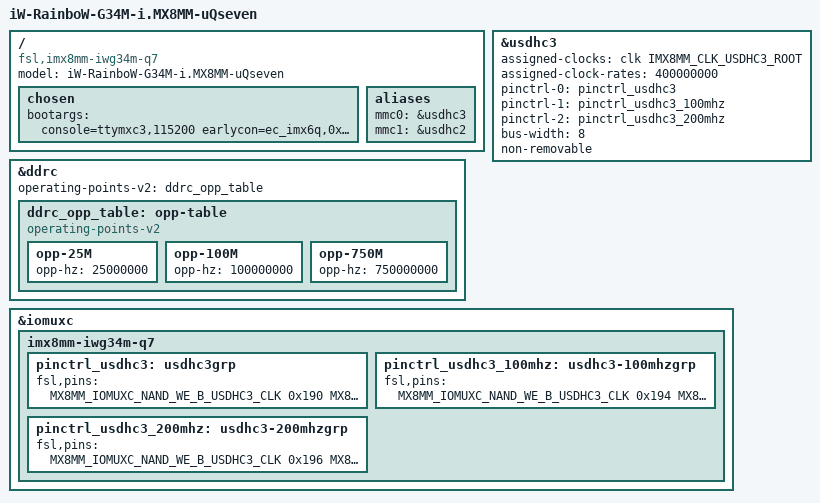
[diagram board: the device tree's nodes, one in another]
// SPDX-License-Identifier: (GPL-2.0+ OR MIT)
/*
 * Copyright 2022 iWave Systems Technologies Pvt Ltd.
 */

/dts-v1/;

#include <dt-bindings/usb/pd.h>
#include "imx8mm-iwg34m-q7.dtsi"

/ {
	model = "iW-RainboW-G34M-i.MX8MM-uQseven";
	compatible = "fsl,imx8mm-iwg34m-q7", "fsl,imx8mm";

	chosen {
		bootargs = "console=ttymxc3,115200 earlycon=ec_imx6q,0x30a60000,115200";
	};

	aliases {
               mmc0 = &usdhc3;
               mmc1 = &usdhc2;
	};
};

&ddrc {
	operating-points-v2 = <&ddrc_opp_table>;

	ddrc_opp_table: opp-table {
		compatible = "operating-points-v2";

		opp-25M {
			opp-hz = /bits/ 64 <25000000>;
		};

		opp-100M {
			opp-hz = /bits/ 64 <100000000>;
		};

		opp-750M {
			opp-hz = /bits/ 64 <750000000>;
		};
	};
};

&usdhc3 {
	assigned-clocks = <&clk IMX8MM_CLK_USDHC3_ROOT>;
	assigned-clock-rates = <400000000>;
	pinctrl-names = "default", "state_100mhz", "state_200mhz";
	pinctrl-0 = <&pinctrl_usdhc3>;
	pinctrl-1 = <&pinctrl_usdhc3_100mhz>;
	pinctrl-2 = <&pinctrl_usdhc3_200mhz>;
	bus-width = <8>;
	non-removable;
	status = "okay";
};

&iomuxc {
	imx8mm-iwg34m-q7 {
		pinctrl_usdhc3: usdhc3grp {
			fsl,pins = <
				MX8MM_IOMUXC_NAND_WE_B_USDHC3_CLK               0x190
				MX8MM_IOMUXC_NAND_WP_B_USDHC3_CMD               0x1d0
				MX8MM_IOMUXC_NAND_DATA04_USDHC3_DATA0           0x1d0
				MX8MM_IOMUXC_NAND_DATA05_USDHC3_DATA1           0x1d0
				MX8MM_IOMUXC_NAND_DATA06_USDHC3_DATA2           0x1d0
				MX8MM_IOMUXC_NAND_DATA06_USDHC3_DATA2           0x1d0
				MX8MM_IOMUXC_NAND_DATA07_USDHC3_DATA3           0x1d0
				MX8MM_IOMUXC_NAND_RE_B_USDHC3_DATA4             0x1d0
				MX8MM_IOMUXC_NAND_CE2_B_USDHC3_DATA5            0x1d0
				MX8MM_IOMUXC_NAND_CE3_B_USDHC3_DATA6            0x1d0
				MX8MM_IOMUXC_NAND_CLE_USDHC3_DATA7              0x1d0
				MX8MM_IOMUXC_NAND_READY_B_SD3_RESET_B	        0x1d4
				MX8MM_IOMUXC_NAND_CE1_B_USDHC3_STROBE           0x190
			>;
		};

		pinctrl_usdhc3_100mhz: usdhc3-100mhzgrp {
			fsl,pins = <
				MX8MM_IOMUXC_NAND_WE_B_USDHC3_CLK               0x194
				MX8MM_IOMUXC_NAND_WP_B_USDHC3_CMD               0x1d4
				MX8MM_IOMUXC_NAND_DATA04_USDHC3_DATA0           0x1d4
				MX8MM_IOMUXC_NAND_DATA05_USDHC3_DATA1           0x1d4
				MX8MM_IOMUXC_NAND_DATA06_USDHC3_DATA2           0x1d4
				MX8MM_IOMUXC_NAND_DATA07_USDHC3_DATA3           0x1d4
				MX8MM_IOMUXC_NAND_RE_B_USDHC3_DATA4             0x1d4
				MX8MM_IOMUXC_NAND_CE2_B_USDHC3_DATA5            0x1d4
				MX8MM_IOMUXC_NAND_CE3_B_USDHC3_DATA6            0x1d4
				MX8MM_IOMUXC_NAND_CLE_USDHC3_DATA7              0x1d4
				MX8MM_IOMUXC_NAND_READY_B_SD3_RESET_B	        0x1d4
				MX8MM_IOMUXC_NAND_CE1_B_USDHC3_STROBE           0x194
			>;
		};

		pinctrl_usdhc3_200mhz: usdhc3-200mhzgrp {
			fsl,pins = <
				MX8MM_IOMUXC_NAND_WE_B_USDHC3_CLK               0x196
				MX8MM_IOMUXC_NAND_WP_B_USDHC3_CMD               0x1d6
				MX8MM_IOMUXC_NAND_DATA04_USDHC3_DATA0           0x1d6
				MX8MM_IOMUXC_NAND_DATA05_USDHC3_DATA1           0x1d6
				MX8MM_IOMUXC_NAND_DATA06_USDHC3_DATA2           0x1d6
				MX8MM_IOMUXC_NAND_DATA07_USDHC3_DATA3           0x1d6
				MX8MM_IOMUXC_NAND_RE_B_USDHC3_DATA4             0x1d6
				MX8MM_IOMUXC_NAND_CE2_B_USDHC3_DATA5            0x1d6
				MX8MM_IOMUXC_NAND_CE3_B_USDHC3_DATA6            0x1d6
				MX8MM_IOMUXC_NAND_CLE_USDHC3_DATA7              0x1d6
				MX8MM_IOMUXC_NAND_READY_B_SD3_RESET_B	        0x1d4
				MX8MM_IOMUXC_NAND_CE1_B_USDHC3_STROBE           0x196
			>;
		};
	};
};
